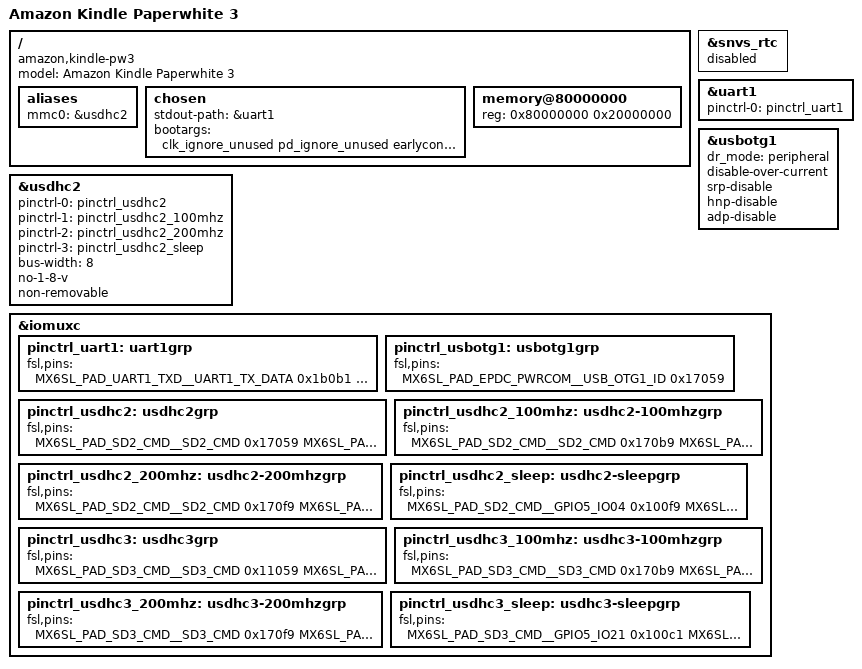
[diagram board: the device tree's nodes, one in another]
// SPDX-License-Identifier: GPL-2.0
/*
 * Device tree for the Amazon Kindle Paperwhite 3
 *
 * Copyright 2025 Ivaylo Ivanov <ivo.ivanov.ivanov1@gmail.com>
 */

/dts-v1/;

#include <dt-bindings/leds/common.h>
#include <dt-bindings/input/input.h>
#include <dt-bindings/gpio/gpio.h>
#include "imx6sl.dtsi"

/* 2d accelerators cause the system to hang. */
/delete-node/ &gpu_2d;
/delete-node/ &gpu_vg;

/ {
	model = "Amazon Kindle Paperwhite 3";
	compatible = "amazon,kindle-pw3", "fsl,imx6sl";

	aliases {
		mmc0 = &usdhc2;
	};

	chosen {
		stdout-path = &uart1;
		bootargs = "clk_ignore_unused pd_ignore_unused earlycon=ec_imx21,0x02020000 console=ttymxc0,115200 keep_bootcon noinitrd root=/dev/mmcblk0p1 rw rootwait";
	};

	memory@80000000 {
		device_type = "memory";
		reg = <0x80000000 0x20000000>;
	};
};

&snvs_rtc {
	/*
	 * We are using the RTC in the PMIC, but this one is not disabled
	 * in imx6sl.dtsi.
	 */
	status = "disabled";
};

&uart1 {
	/* labelled as P800 SERIAL DEBUG on the motherboard */
	pinctrl-names = "default";
	pinctrl-0 = <&pinctrl_uart1>;
	status = "okay";
};

&usdhc2 {
	pinctrl-names = "default", "state_100mhz", "state_200mhz", "sleep";
	pinctrl-0 = <&pinctrl_usdhc2>;
	pinctrl-1 = <&pinctrl_usdhc2_100mhz>;
	pinctrl-2 = <&pinctrl_usdhc2_200mhz>;
	pinctrl-3 = <&pinctrl_usdhc2_sleep>;
	bus-width = <8>;
	no-1-8-v;
	non-removable;
	status = "okay";

	/* internal eMMC */
};

&usbotg1 {
	dr_mode = "peripheral";
	disable-over-current;
	srp-disable;
	hnp-disable;
	adp-disable;
	status = "okay";
};

&iomuxc {
	pinctrl_uart1: uart1grp {
		fsl,pins = <
			MX6SL_PAD_UART1_TXD__UART1_TX_DATA 0x1b0b1
			MX6SL_PAD_UART1_RXD__UART1_RX_DATA 0x1b0b1
		>;
	};

	pinctrl_usbotg1: usbotg1grp {
		fsl,pins = <
			MX6SL_PAD_EPDC_PWRCOM__USB_OTG1_ID 0x17059
		>;
	};

	pinctrl_usdhc2: usdhc2grp {
		fsl,pins = <
			MX6SL_PAD_SD2_CMD__SD2_CMD		0x17059
			MX6SL_PAD_SD2_CLK__SD2_CLK		0x13059
			MX6SL_PAD_SD2_DAT0__SD2_DATA0		0x17059
			MX6SL_PAD_SD2_DAT1__SD2_DATA1		0x17059
			MX6SL_PAD_SD2_DAT2__SD2_DATA2		0x17059
			MX6SL_PAD_SD2_DAT3__SD2_DATA3		0x17059
			MX6SL_PAD_SD2_DAT4__GPIO5_IO02		0x1b0b1
		>;
	};

	pinctrl_usdhc2_100mhz: usdhc2-100mhzgrp {
		fsl,pins = <
			MX6SL_PAD_SD2_CMD__SD2_CMD		0x170b9
			MX6SL_PAD_SD2_CLK__SD2_CLK		0x130b9
			MX6SL_PAD_SD2_DAT0__SD2_DATA0		0x170b9
			MX6SL_PAD_SD2_DAT1__SD2_DATA1		0x170b9
			MX6SL_PAD_SD2_DAT2__SD2_DATA2		0x170b9
			MX6SL_PAD_SD2_DAT3__SD2_DATA3		0x170b9
		>;
	};

	pinctrl_usdhc2_200mhz: usdhc2-200mhzgrp {
		fsl,pins = <
			MX6SL_PAD_SD2_CMD__SD2_CMD		0x170f9
			MX6SL_PAD_SD2_CLK__SD2_CLK		0x130f9
			MX6SL_PAD_SD2_DAT0__SD2_DATA0		0x170f9
			MX6SL_PAD_SD2_DAT1__SD2_DATA1		0x170f9
			MX6SL_PAD_SD2_DAT2__SD2_DATA2		0x170f9
			MX6SL_PAD_SD2_DAT3__SD2_DATA3		0x170f9
		>;
	};

	pinctrl_usdhc2_sleep: usdhc2-sleepgrp {
		fsl,pins = <
			MX6SL_PAD_SD2_CMD__GPIO5_IO04		0x100f9
			MX6SL_PAD_SD2_CLK__GPIO5_IO05		0x100f9
			MX6SL_PAD_SD2_DAT0__GPIO5_IO01		0x100f9
			MX6SL_PAD_SD2_DAT1__GPIO4_IO30		0x100f9
			MX6SL_PAD_SD2_DAT2__GPIO5_IO03		0x100f9
			MX6SL_PAD_SD2_DAT3__GPIO4_IO28		0x100f9
		>;
	};

	pinctrl_usdhc3: usdhc3grp {
		fsl,pins = <
			MX6SL_PAD_SD3_CMD__SD3_CMD	0x11059
			MX6SL_PAD_SD3_CLK__SD3_CLK	0x11059
			MX6SL_PAD_SD3_DAT0__SD3_DATA0	0x11059
			MX6SL_PAD_SD3_DAT1__SD3_DATA1	0x11059
			MX6SL_PAD_SD3_DAT2__SD3_DATA2	0x11059
			MX6SL_PAD_SD3_DAT3__SD3_DATA3	0x11059
		>;
	};

	pinctrl_usdhc3_100mhz: usdhc3-100mhzgrp {
		fsl,pins = <
			MX6SL_PAD_SD3_CMD__SD3_CMD	0x170b9
			MX6SL_PAD_SD3_CLK__SD3_CLK	0x170b9
			MX6SL_PAD_SD3_DAT0__SD3_DATA0	0x170b9
			MX6SL_PAD_SD3_DAT1__SD3_DATA1	0x170b9
			MX6SL_PAD_SD3_DAT2__SD3_DATA2	0x170b9
			MX6SL_PAD_SD3_DAT3__SD3_DATA3	0x170b9
		>;
	};

	pinctrl_usdhc3_200mhz: usdhc3-200mhzgrp {
		fsl,pins = <
			MX6SL_PAD_SD3_CMD__SD3_CMD	0x170f9
			MX6SL_PAD_SD3_CLK__SD3_CLK	0x170f9
			MX6SL_PAD_SD3_DAT0__SD3_DATA0	0x170f9
			MX6SL_PAD_SD3_DAT1__SD3_DATA1	0x170f9
			MX6SL_PAD_SD3_DAT2__SD3_DATA2	0x170f9
			MX6SL_PAD_SD3_DAT3__SD3_DATA3	0x170f9
		>;
	};

	pinctrl_usdhc3_sleep: usdhc3-sleepgrp {
		fsl,pins = <
			MX6SL_PAD_SD3_CMD__GPIO5_IO21	0x100c1
			MX6SL_PAD_SD3_CLK__GPIO5_IO18	0x100c1
			MX6SL_PAD_SD3_DAT0__GPIO5_IO19	0x100c1
			MX6SL_PAD_SD3_DAT1__GPIO5_IO20	0x100c1
			MX6SL_PAD_SD3_DAT2__GPIO5_IO16	0x100c1
			MX6SL_PAD_SD3_DAT3__GPIO5_IO17	0x100c1
		>;
	};
};
